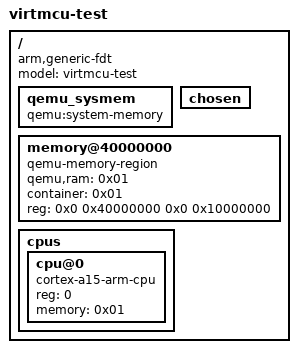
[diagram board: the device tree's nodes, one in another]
/dts-v1/;
/ {
    model = "virtmcu-test"; compatible = "arm,generic-fdt"; #address-cells = <2>; #size-cells = <2>;
    qemu_sysmem: qemu_sysmem { compatible = "qemu:system-memory"; phandle = <0x01>; };
    chosen {};
    memory@40000000 { compatible = "qemu-memory-region"; qemu,ram = <0x01>; container = <0x01>; reg = <0x0 0x40000000 0x0 0x10000000>; };
    cpus { #address-cells = <1>; #size-cells = <0>; cpu@0 { device_type = "cpu"; compatible = "cortex-a15-arm-cpu"; reg = <0>; memory = <0x01>; }; };
};
